# MM32SPIN2x register map
File version: 1.90
CPU: CM0 r0p0, little endian, no MPU, no FPU, 2 interrupt priority bits
Registers are 32-bit, read-write, reset 0x0 unless marked. A register's access mark holds for its fields unless they carry their own. Offsets are from the block's base; [hi:lo] are bit positions; {n}, {i} and the like mark numbered series.

## BKP — Backup registers
Base 0x4000280C
{0x0+4i} DR{i} (i=1..20) — Backup data register(BKP_DR)
  [15:0] D — Backup data

## COMP — comparator
Base 0x40013C00
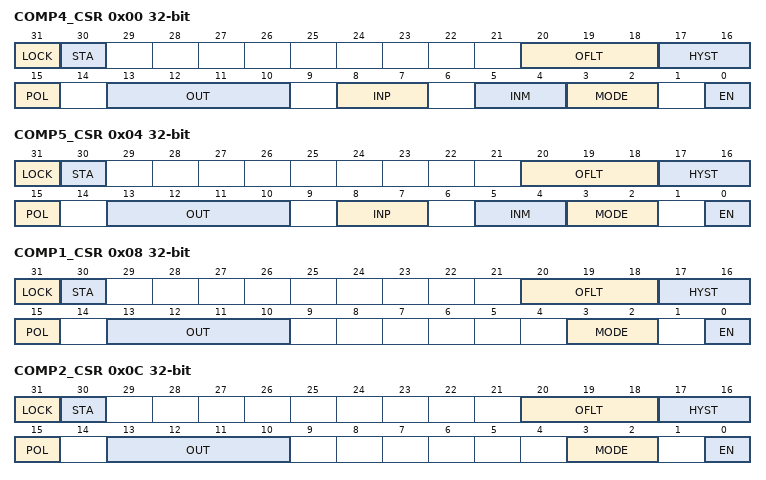
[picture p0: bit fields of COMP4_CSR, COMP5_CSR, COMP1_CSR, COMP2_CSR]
0x00 COMP4_CSR
  [31] LOCK — Comparator 4 lock
  [30] STA — Comparator 4 output status
  [20:18] OFLT — Comparator 4 output filter
  [17:16] HYST — Comparator 4 hysteresis
  [15] POL — Comparator 4 output polarity
  [13:10] OUT — Comparator 4 output selection
  [8:7] INP — Comparator 4 normal phase input selection
  [5:4] INM — Comparator 4 inverting input selection
  [3:2] MODE — Comparator 4 mode
  [0] EN — Comparator 4 enable
0x04 COMP5_CSR
  [31] LOCK — Comparator 5 lock
  [30] STA — Comparator 5 output status
  [20:18] OFLT — Comparator 5 output filter
  [17:16] HYST — Comparator 5 hysteresis
  [15] POL — Comparator 5 output polarity
  [13:10] OUT — Comparator 5 output selection
  [8:7] INP — Comparator 5 normal phase input selection
  [5:4] INM — Comparator 5 inverting input selection
  [3:2] MODE — Comparator 5 mode
  [0] EN — Comparator 5 enable
0x08 COMP1_CSR
  [31] LOCK — Comparator 1 lock
  [30] STA — Comparator 1 output status
  [20:18] OFLT — Comparator 1 output filter
  [17:16] HYST — Comparator 1 hysteresis
  [15] POL — Comparator 1 output polarity
  [13:10] OUT — Comparator 1 output selection
  [3:2] MODE — Comparator 1 mode
  [0] EN — Comparator 1 enable
0x0C COMP2_CSR
  [31] LOCK — Comparator 2 lock
  [30] STA — Comparator 2 output status
  [20:18] OFLT — Comparator 2 output filter
  [17:16] HYST — Comparator 2 hysteresis
  [15] POL — Comparator 2 output polarity
  [13:10] OUT — Comparator 2 output selection
  [3:2] MODE — Comparator 2 mode
  [0] EN — Comparator 2 enable
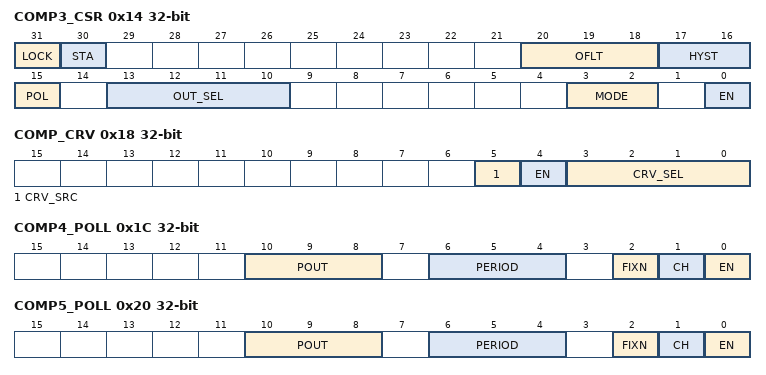
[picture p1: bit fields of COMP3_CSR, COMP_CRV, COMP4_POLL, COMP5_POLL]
0x14 COMP3_CSR
  [31] LOCK — Comparator 3 lock
  [30] STA — Comparator 3 output status
  [20:18] OFLT — Comparator 3 output filter
  [17:16] HYST — Comparator 3 hysteresis
  [15] POL — Comparator 3 output polarity
  [13:10] OUT_SEL — Comparator 3 output selection
  [3:2] MODE — Comparator 3 mode
  [0] EN — Comparator 3 enable
0x18 COMP_CRV
  [5] CRV_SRC — Comparator external refer-ence voltage source select
  [4] EN — Comparator external referencevoltage enable
  [3:0] CRV_SEL — Comparator external referencevoltage select
0x1C COMP4_POLL
  [10:8] POUT — Comparator 4 Polling output
  [6:4] PERIOD — Comparator 4 polling wait cycle
  [2] FIXN — Comparator 4 Polling inverting input fix
  [1] CH — Comparator 4 polling channel
  [0] EN — Comparator 4 polling enable
0x20 COMP5_POLL
  [10:8] POUT — Comparator 5 Polling output
  [6:4] PERIOD — Comparator 5 polling wait cycle
  [2] FIXN — Comparator 5 Polling inverting input fix
  [1] CH — Comparator 5 polling channel
  [0] EN — Comparator 5 polling enable

## CRC — CRC calculation unit
Base 0x40023000
0x00 DR reset 0xFFFFFFFF — Data register
  [31:0] DR — Data register bits
0x04 IDR — Independent data register
  [7:0] IDR — General-purpose 8-bit data register bits
0x08 CR wo — Control register
  [0] RESET — CRC reset

## DBG — Debug support
Base 0x40013400
0x00 IDCODE ro
  [31:0] DEV_ID — Device identifier
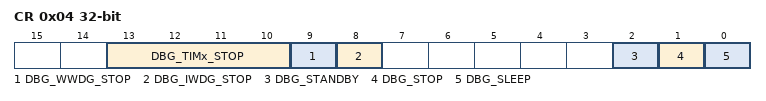
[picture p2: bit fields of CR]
0x04 CR wo
  [13:10] DBG_TIMx_STOP — TIMx counter stopped when core is halted
  [9] DBG_WWDG_STOP — Debug window watchdog when core is halted
  [8] DBG_IWDG_STOP — Debug independent watchdog stopped when core is stopped
  [2] DBG_STANDBY — Debug Standby mode
  [1] DBG_STOP — Debug Stop mode
  [0] DBG_SLEEP — Debug Sleep mode

## DIV — Hardware divider
Base 0x40030000
0x00 DVDR
  [31:0] DIVIDEND — Dividend data
0x04 DVSR reset 0x1
  [31:0] DIVISOR — Divisor data
0x08 QUOTR ro
  [31:0] QUOTIENT — Quotient data
0x0C RMDR ro
  [31:0] REMAINDER — Remainder data
0x10 SR ro
  [0] OVF — Overflow flag
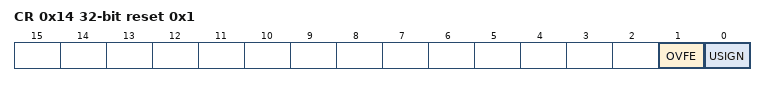
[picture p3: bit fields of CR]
0x14 CR reset 0x1
  [1] OVFE — Overflow interrupt enable
  [0] USIGN — unsigned enable
